VERSION "created by canmatrix"

NS_ :

BS_:

BU_:

BO_ 257 0x101: 1 Vector__XXX
 SG_ Range : 0|8@1- (1,0) [-128|127] "Status" Vector__XXX

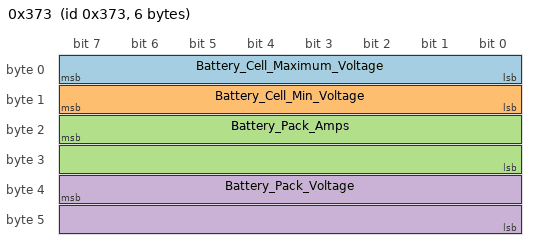
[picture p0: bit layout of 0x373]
BO_ 883 0x373: 6 Vector__XXX
 SG_ Battery_Cell_Maximum_Voltage : 0|8@1- (0.01,210) [208.72|211.27] "Volts" Vector__XXX
 SG_ Battery_Cell_Min_Voltage : 8|8@1- (0.01,210) [208.72|211.27] "None" Vector__XXX
 SG_ Battery_Pack_Amps : 23|16@0- (0.01,-32768) [-33095.68|-32440.33] "Amps" Vector__XXX
 SG_ Battery_Pack_Voltage : 39|16@0- (0.01,0) [-327.68|327.67] "Volts" Vector__XXX

BO_ 838 0x346: 8 Vector__XXX
 SG_ Range : 56|8@1- (1,0) [-128|127] "Kilometers" Vector__XXX

BO_ 533 0x215: 2 Vector__XXX
 SG_ Vehicle_Speed : 7|16@0- (0.0078125,0) [-256.0000000|255.9921875] "km/h" Vector__XXX

BO_ 528 0x210: 2 Vector__XXX
 SG_ Accelerator_Pedal_Percentage : 8|8@1- (0.4,0) [-51.2|50.8] "Percentage" Vector__XXX

CM_ BO_ 257  "Key Status";
CM_ BO_ 883  "Traction Battery Info";
CM_ BO_ 838  "Range and Handbrake";
CM_ BO_ 533  "Vehicle Speed";
CM_ BO_ 528  "Accelerator Pedal Percentage";

BA_DEF_ SG_ "GenSigStartValue" FLOAT 0 100000000000;

BA_ "GenSigStartValue" SG_ 883 Battery_Cell_Maximum_Voltage -128;
BA_ "GenSigStartValue" SG_ 883 Battery_Cell_Min_Voltage -128;
BA_ "GenSigStartValue" SG_ 883 Battery_Pack_Amps -32768;

VAL_ 257 Range 0 "Off" 4 "On";
